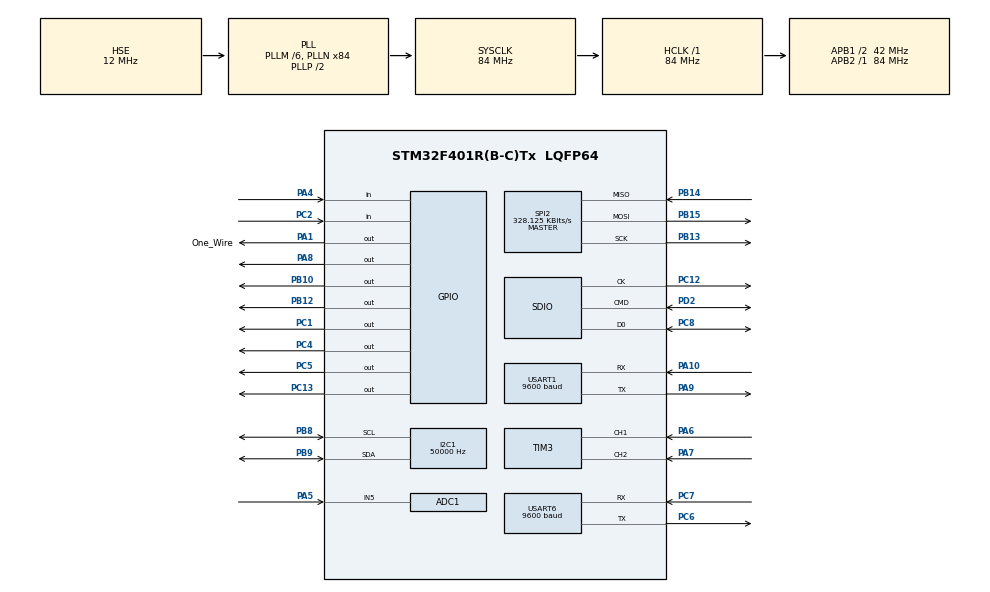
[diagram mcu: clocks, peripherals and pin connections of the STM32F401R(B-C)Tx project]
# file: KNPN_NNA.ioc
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ADC1.Channel-0\#ChannelRegularConversion=ADC_CHANNEL_5
ADC1.NbrOfConversionFlag=1
ADC1.Rank-0\#ChannelRegularConversion=1
ADC1.SamplingTime-0\#ChannelRegularConversion=ADC_SAMPLETIME_3CYCLES
ADC1.master=1
FATFS._FS_LOCK=7
FATFS._MAX_SS=4096
FATFS._USE_LFN=1
I2C1.ClockSpeed=50000
Mcu.Family=STM32F4
Mcu.Name=STM32F401R(B-C)Tx
Mcu.Package=LQFP64
NVIC.PriorityGroup=NVIC_PRIORITYGROUP_4
NVIC.TIM3_IRQn=true\:0\:0\:false\:false\:true\:true\:true
NVIC.USART6_IRQn=true\:0\:0\:false\:false\:true\:true\:true
PA1.GPIO_Label=One_Wire
PA1.Signal=GPIO_Output
PA10.Mode=Asynchronous
PA10.Signal=USART1_RX
PA4.Signal=GPIO_Input
PA5.Signal=ADCx_IN5
PA6.Signal=S_TIM3_CH1
PA7.Signal=S_TIM3_CH2
PA8.Signal=GPIO_Output
PA9.Mode=Asynchronous
PA9.Signal=USART1_TX
PB10.Signal=GPIO_Output
PB12.Signal=GPIO_Output
PB13.Mode=Full_Duplex_Master
PB13.Signal=SPI2_SCK
PB14.Mode=Full_Duplex_Master
PB14.Signal=SPI2_MISO
PB15.Mode=Full_Duplex_Master
PB15.Signal=SPI2_MOSI
PB8.Mode=I2C
PB8.Signal=I2C1_SCL
PB9.Mode=I2C
PB9.Signal=I2C1_SDA
PC1.Signal=GPIO_Output
PC12.Mode=SD_1_bit
PC12.Signal=SDIO_CK
PC13-ANTI_TAMP.Signal=GPIO_Output
PC14-OSC32_IN.Mode=LSE-External-Oscillator
PC14-OSC32_IN.Signal=RCC_OSC32_IN
PC15-OSC32_OUT.Mode=LSE-External-Oscillator
PC15-OSC32_OUT.Signal=RCC_OSC32_OUT
PC2.Signal=GPIO_Input
PC4.Signal=GPIO_Output
PC5.Signal=GPIO_Output
PC6.Mode=Asynchronous
PC6.Signal=USART6_TX
PC7.Mode=Asynchronous
PC7.Signal=USART6_RX
PC8.Mode=SD_1_bit
PC8.Signal=SDIO_D0
PD2.Mode=SD_1_bit
PD2.Signal=SDIO_CMD
PH0\ -\ OSC_IN.Mode=HSE-External-Oscillator
PH0\ -\ OSC_IN.Signal=RCC_OSC_IN
PH1\ -\ OSC_OUT.Mode=HSE-External-Oscillator
PH1\ -\ OSC_OUT.Signal=RCC_OSC_OUT
ProjectManager.HeapSize=0x200
ProjectManager.StackSize=0x400
ProjectManager.TargetToolchain=STM32CubeIDE
RCC.48MHZClocksFreq_Value=42000000
RCC.AHBFreq_Value=84000000
RCC.APB1CLKDivider=RCC_HCLK_DIV2
RCC.APB1Freq_Value=42000000
RCC.APB1TimFreq_Value=84000000
RCC.APB2Freq_Value=84000000
RCC.APB2TimFreq_Value=84000000
RCC.CortexFreq_Value=84000000
RCC.HCLKFreq_Value=84000000
RCC.HSE_VALUE=12000000
RCC.HSI_VALUE=16000000
RCC.PLLM=6
RCC.PLLN=84
RCC.PLLSourceVirtual=RCC_PLLSOURCE_HSE
RCC.SYSCLKFreq_VALUE=84000000
RCC.SYSCLKSource=RCC_SYSCLKSOURCE_PLLCLK
RCC.VCOOutputFreq_Value=168000000
SH.ADCx_IN5.0=ADC1_IN5,IN5
SH.S_TIM3_CH1.0=TIM3_CH1,Encoder_Interface
SH.S_TIM3_CH2.0=TIM3_CH2,Encoder_Interface
SPI2.BaudRatePrescaler=SPI_BAUDRATEPRESCALER_128
SPI2.CalculateBaudRate=328.125 KBits/s
SPI2.Direction=SPI_DIRECTION_2LINES
SPI2.Mode=SPI_MODE_MASTER
SPI2.VirtualType=VM_MASTER
TIM3.Channel-Output\ Compare3\ No\ Output=TIM_CHANNEL_3
TIM3.EncoderMode=TIM_ENCODERMODE_TI12
USART1.BaudRate=9600
USART1.VirtualMode=VM_ASYNC
USART6.BaudRate=9600
USART6.VirtualMode=VM_ASYNC
VP_FATFS_VS_SDIO.Mode=SDIO
VP_TIM3_VS_no_output3.Mode=Output Compare3 No Output
board=custom

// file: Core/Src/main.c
/* USER CODE BEGIN Header */
/**
  ******************************************************************************
  * @file           : main.c
  * @brief          : Main program body
  ******************************************************************************
  * @attention
  *
  * Copyright (c) 2022 STMicroelectronics.
  * All rights reserved.
  *
  * This software is licensed under terms that can be found in the LICENSE file
  * in the root directory of this software component.
  * If no LICENSE file comes with this software, it is provided AS-IS.
  *
  ******************************************************************************
  */
/* USER CODE END Header */
#include "main.h"
#include "fatfs.h"

ADC_HandleTypeDef hadc1;

I2C_HandleTypeDef hi2c1;

SD_HandleTypeDef hsd;

SPI_HandleTypeDef hspi2;

TIM_HandleTypeDef htim3;

UART_HandleTypeDef huart1;
UART_HandleTypeDef huart6;

void SystemClock_Config(void);
static void MX_GPIO_Init(void);
static void MX_SPI2_Init(void);
static void MX_USART1_UART_Init(void);
static void MX_I2C1_Init(void);
static void MX_TIM3_Init(void);
static void MX_SDIO_SD_Init(void);
static void MX_USART6_UART_Init(void);
static void MX_ADC1_Init(void);

/* USER CODE BEGIN 0 */
int app_main();
/* USER CODE END 0 */

int main(void)
{

  /* MCU Configuration--------------------------------------------------------*/

  /* Reset of all peripherals, Initializes the Flash interface and the Systick. */
  HAL_Init();

  /* Configure the system clock */
  SystemClock_Config();

  /* Initialize all configured peripherals */
  MX_GPIO_Init();
  MX_SPI2_Init();
  MX_USART1_UART_Init();
  MX_I2C1_Init();
  MX_TIM3_Init();
  MX_SDIO_SD_Init();
  MX_FATFS_Init();
  MX_USART6_UART_Init();
  MX_ADC1_Init();

  /* Infinite loop */
  while (1)
  {

    /* USER CODE BEGIN 3 */
	  app_main();
  }

  return 0;
  /* USER CODE END 3 */
}

void SystemClock_Config(void)
{
  RCC_OscInitTypeDef RCC_OscInitStruct = {0};
  RCC_ClkInitTypeDef RCC_ClkInitStruct = {0};

  /** Configure the main internal regulator output voltage
  */
  __HAL_RCC_PWR_CLK_ENABLE();
  __HAL_PWR_VOLTAGESCALING_CONFIG(PWR_REGULATOR_VOLTAGE_SCALE2);
  /** Initializes the RCC Oscillators according to the specified parameters
  * in the RCC_OscInitTypeDef structure.
  */
  RCC_OscInitStruct.OscillatorType = RCC_OSCILLATORTYPE_HSE;
  RCC_OscInitStruct.HSEState = RCC_HSE_ON;
  RCC_OscInitStruct.PLL.PLLState = RCC_PLL_ON;
  RCC_OscInitStruct.PLL.PLLSource = RCC_PLLSOURCE_HSE;
  RCC_OscInitStruct.PLL.PLLM = 6;
  RCC_OscInitStruct.PLL.PLLN = 84;
  RCC_OscInitStruct.PLL.PLLP = RCC_PLLP_DIV2;
  RCC_OscInitStruct.PLL.PLLQ = 4;
  if (HAL_RCC_OscConfig(&RCC_OscInitStruct) != HAL_OK)
  {
    Error_Handler();
  }
  /** Initializes the CPU, AHB and APB buses clocks
  */
  RCC_ClkInitStruct.ClockType = RCC_CLOCKTYPE_HCLK|RCC_CLOCKTYPE_SYSCLK
                              |RCC_CLOCKTYPE_PCLK1|RCC_CLOCKTYPE_PCLK2;
  RCC_ClkInitStruct.SYSCLKSource = RCC_SYSCLKSOURCE_PLLCLK;
  RCC_ClkInitStruct.AHBCLKDivider = RCC_SYSCLK_DIV1;
  RCC_ClkInitStruct.APB1CLKDivider = RCC_HCLK_DIV2;
  RCC_ClkInitStruct.APB2CLKDivider = RCC_HCLK_DIV1;

  if (HAL_RCC_ClockConfig(&RCC_ClkInitStruct, FLASH_LATENCY_2) != HAL_OK)
  {
    Error_Handler();
  }
}

static void MX_ADC1_Init(void)
{

  ADC_ChannelConfTypeDef sConfig = {0};

  /** Configure the global features of the ADC (Clock, Resolution, Data Alignment and number of conversion)
  */
  hadc1.Instance = ADC1;
  hadc1.Init.ClockPrescaler = ADC_CLOCK_SYNC_PCLK_DIV4;
  hadc1.Init.Resolution = ADC_RESOLUTION_12B;
  hadc1.Init.ScanConvMode = DISABLE;
  hadc1.Init.ContinuousConvMode = DISABLE;
  hadc1.Init.DiscontinuousConvMode = DISABLE;
  hadc1.Init.ExternalTrigConvEdge = ADC_EXTERNALTRIGCONVEDGE_NONE;
  hadc1.Init.ExternalTrigConv = ADC_SOFTWARE_START;
  hadc1.Init.DataAlign = ADC_DATAALIGN_RIGHT;
  hadc1.Init.NbrOfConversion = 1;
  hadc1.Init.DMAContinuousRequests = DISABLE;
  hadc1.Init.EOCSelection = ADC_EOC_SINGLE_CONV;
  if (HAL_ADC_Init(&hadc1) != HAL_OK)
  {
    Error_Handler();
  }
  /** Configure for the selected ADC regular channel its corresponding rank in the sequencer and its sample time.
  */
  sConfig.Channel = ADC_CHANNEL_5;
  sConfig.Rank = 1;
  sConfig.SamplingTime = ADC_SAMPLETIME_3CYCLES;
  if (HAL_ADC_ConfigChannel(&hadc1, &sConfig) != HAL_OK)
  {
    Error_Handler();
  }

}

static void MX_I2C1_Init(void)
{

  hi2c1.Instance = I2C1;
  hi2c1.Init.ClockSpeed = 50000;
  hi2c1.Init.DutyCycle = I2C_DUTYCYCLE_2;
  hi2c1.Init.OwnAddress1 = 0;
  hi2c1.Init.AddressingMode = I2C_ADDRESSINGMODE_7BIT;
  hi2c1.Init.DualAddressMode = I2C_DUALADDRESS_DISABLE;
  hi2c1.Init.OwnAddress2 = 0;
  hi2c1.Init.GeneralCallMode = I2C_GENERALCALL_DISABLE;
  hi2c1.Init.NoStretchMode = I2C_NOSTRETCH_DISABLE;
  if (HAL_I2C_Init(&hi2c1) != HAL_OK)
  {
    Error_Handler();
  }

}

static void MX_SDIO_SD_Init(void)
{

  hsd.Instance = SDIO;
  hsd.Init.ClockEdge = SDIO_CLOCK_EDGE_RISING;
  hsd.Init.ClockBypass = SDIO_CLOCK_BYPASS_DISABLE;
  hsd.Init.ClockPowerSave = SDIO_CLOCK_POWER_SAVE_DISABLE;
  hsd.Init.BusWide = SDIO_BUS_WIDE_1B;
  hsd.Init.HardwareFlowControl = SDIO_HARDWARE_FLOW_CONTROL_DISABLE;
  hsd.Init.ClockDiv = 0;

}

static void MX_SPI2_Init(void)
{

  /* SPI2 parameter configuration*/
  hspi2.Instance = SPI2;
  hspi2.Init.Mode = SPI_MODE_MASTER;
  hspi2.Init.Direction = SPI_DIRECTION_2LINES;
  hspi2.Init.DataSize = SPI_DATASIZE_8BIT;
  hspi2.Init.CLKPolarity = SPI_POLARITY_LOW;
  hspi2.Init.CLKPhase = SPI_PHASE_1EDGE;
  hspi2.Init.NSS = SPI_NSS_SOFT;
  hspi2.Init.BaudRatePrescaler = SPI_BAUDRATEPRESCALER_128;
  hspi2.Init.FirstBit = SPI_FIRSTBIT_MSB;
  hspi2.Init.TIMode = SPI_TIMODE_DISABLE;
  hspi2.Init.CRCCalculation = SPI_CRCCALCULATION_DISABLE;
  hspi2.Init.CRCPolynomial = 10;
  if (HAL_SPI_Init(&hspi2) != HAL_OK)
  {
    Error_Handler();
  }

}

static void MX_TIM3_Init(void)
{

  TIM_Encoder_InitTypeDef sConfig = {0};
  TIM_MasterConfigTypeDef sMasterConfig = {0};
  TIM_OC_InitTypeDef sConfigOC = {0};

  htim3.Instance = TIM3;
  htim3.Init.Prescaler = 0;
  htim3.Init.CounterMode = TIM_COUNTERMODE_UP;
  htim3.Init.Period = 65535;
  htim3.Init.ClockDivision = TIM_CLOCKDIVISION_DIV1;
  htim3.Init.AutoReloadPreload = TIM_AUTORELOAD_PRELOAD_DISABLE;
  if (HAL_TIM_OC_Init(&htim3) != HAL_OK)
  {
    Error_Handler();
  }
  sConfig.EncoderMode = TIM_ENCODERMODE_TI12;
  sConfig.IC1Polarity = TIM_ICPOLARITY_RISING;
  sConfig.IC1Selection = TIM_ICSELECTION_DIRECTTI;
  sConfig.IC1Prescaler = TIM_ICPSC_DIV1;
  sConfig.IC1Filter = 0;
  sConfig.IC2Polarity = TIM_ICPOLARITY_RISING;
  sConfig.IC2Selection = TIM_ICSELECTION_DIRECTTI;
  sConfig.IC2Prescaler = TIM_ICPSC_DIV1;
  sConfig.IC2Filter = 0;
  if (HAL_TIM_Encoder_Init(&htim3, &sConfig) != HAL_OK)
  {
    Error_Handler();
  }
  sMasterConfig.MasterOutputTrigger = TIM_TRGO_RESET;
  sMasterConfig.MasterSlaveMode = TIM_MASTERSLAVEMODE_DISABLE;
  if (HAL_TIMEx_MasterConfigSynchronization(&htim3, &sMasterConfig) != HAL_OK)
  {
    Error_Handler();
  }
  sConfigOC.OCMode = TIM_OCMODE_TIMING;
  sConfigOC.Pulse = 0;
  sConfigOC.OCPolarity = TIM_OCPOLARITY_HIGH;
  sConfigOC.OCFastMode = TIM_OCFAST_DISABLE;
  if (HAL_TIM_OC_ConfigChannel(&htim3, &sConfigOC, TIM_CHANNEL_3) != HAL_OK)
  {
    Error_Handler();
  }

}

static void MX_USART1_UART_Init(void)
{

  huart1.Instance = USART1;
  huart1.Init.BaudRate = 9600;
  huart1.Init.WordLength = UART_WORDLENGTH_8B;
  huart1.Init.StopBits = UART_STOPBITS_1;
  huart1.Init.Parity = UART_PARITY_NONE;
  huart1.Init.Mode = UART_MODE_TX_RX;
  huart1.Init.HwFlowCtl = UART_HWCONTROL_NONE;
  huart1.Init.OverSampling = UART_OVERSAMPLING_16;
  if (HAL_UART_Init(&huart1) != HAL_OK)
  {
    Error_Handler();
  }

}

static void MX_USART6_UART_Init(void)
{

  huart6.Instance = USART6;
  huart6.Init.BaudRate = 9600;
  huart6.Init.WordLength = UART_WORDLENGTH_8B;
  huart6.Init.StopBits = UART_STOPBITS_1;
  huart6.Init.Parity = UART_PARITY_NONE;
  huart6.Init.Mode = UART_MODE_TX_RX;
  huart6.Init.HwFlowCtl = UART_HWCONTROL_NONE;
  huart6.Init.OverSampling = UART_OVERSAMPLING_16;
  if (HAL_UART_Init(&huart6) != HAL_OK)
  {
    Error_Handler();
  }

}

static void MX_GPIO_Init(void)
{
  GPIO_InitTypeDef GPIO_InitStruct = {0};

  /* GPIO Ports Clock Enable */
  __HAL_RCC_GPIOC_CLK_ENABLE();
  __HAL_RCC_GPIOH_CLK_ENABLE();
  __HAL_RCC_GPIOA_CLK_ENABLE();
  __HAL_RCC_GPIOB_CLK_ENABLE();
  __HAL_RCC_GPIOD_CLK_ENABLE();

  /*Configure GPIO pin Output Level */
  HAL_GPIO_WritePin(GPIOC, GPIO_PIN_13|GPIO_PIN_1|GPIO_PIN_4|GPIO_PIN_5, GPIO_PIN_RESET);

  /*Configure GPIO pin Output Level */
  HAL_GPIO_WritePin(GPIOA, One_Wire_Pin|GPIO_PIN_8, GPIO_PIN_RESET);

  /*Configure GPIO pin Output Level */
  HAL_GPIO_WritePin(GPIOB, GPIO_PIN_10|GPIO_PIN_12, GPIO_PIN_RESET);

  /*Configure GPIO pins : PC13 PC1 PC4 PC5 */
  GPIO_InitStruct.Pin = GPIO_PIN_13|GPIO_PIN_1|GPIO_PIN_4|GPIO_PIN_5;
  GPIO_InitStruct.Mode = GPIO_MODE_OUTPUT_PP;
  GPIO_InitStruct.Pull = GPIO_NOPULL;
  GPIO_InitStruct.Speed = GPIO_SPEED_FREQ_LOW;
  HAL_GPIO_Init(GPIOC, &GPIO_InitStruct);

  /*Configure GPIO pin : PC2 */
  GPIO_InitStruct.Pin = GPIO_PIN_2;
  GPIO_InitStruct.Mode = GPIO_MODE_INPUT;
  GPIO_InitStruct.Pull = GPIO_NOPULL;
  HAL_GPIO_Init(GPIOC, &GPIO_InitStruct);

  /*Configure GPIO pins : One_Wire_Pin PA8 */
  GPIO_InitStruct.Pin = One_Wire_Pin|GPIO_PIN_8;
  GPIO_InitStruct.Mode = GPIO_MODE_OUTPUT_PP;
  GPIO_InitStruct.Pull = GPIO_NOPULL;
  GPIO_InitStruct.Speed = GPIO_SPEED_FREQ_LOW;
  HAL_GPIO_Init(GPIOA, &GPIO_InitStruct);

  /*Configure GPIO pin : PA4 */
  GPIO_InitStruct.Pin = GPIO_PIN_4;
  GPIO_InitStruct.Mode = GPIO_MODE_INPUT;
  GPIO_InitStruct.Pull = GPIO_NOPULL;
  HAL_GPIO_Init(GPIOA, &GPIO_InitStruct);

  /*Configure GPIO pins : PB10 PB12 */
  GPIO_InitStruct.Pin = GPIO_PIN_10|GPIO_PIN_12;
  GPIO_InitStruct.Mode = GPIO_MODE_OUTPUT_PP;
  GPIO_InitStruct.Pull = GPIO_NOPULL;
  GPIO_InitStruct.Speed = GPIO_SPEED_FREQ_LOW;
  HAL_GPIO_Init(GPIOB, &GPIO_InitStruct);

}

void Error_Handler(void)
{
  __disable_irq();
  while (1)
  {
  }
}
